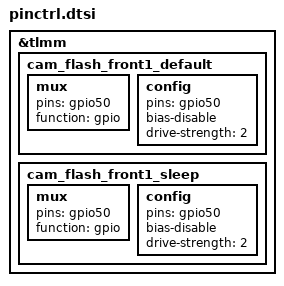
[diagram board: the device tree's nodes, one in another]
/* From stock msm8937-pinctrl.dtsi */
&tlmm {
	cam_flash_front1_default: cam_flash_front1_default {
		mux {
			pins = "gpio50";
			function = "gpio";
		};

		config {
			pins = "gpio50";
			bias-disable;
			drive-strength = <2>;
		};
	};

	cam_flash_front1_sleep: cam_flash_front1_sleep {
		mux {
			pins = "gpio50";
			function = "gpio";
		};

		config {
			pins = "gpio50";
			bias-disable; /* No PULL */
			drive-strength = <2>; /* 2 MA */
		};
	};
};
